# NANO100AN_v1 register map
File version: 1.0
Registers are 32-bit, read-write, reset 0x0 unless marked. A register's access mark holds for its fields unless they carry their own. Offsets are from the block's base; [hi:lo] are bit positions; 'fields as' and 'values as' point back to an identical list.

## SPI0 — SPI Register Map
Base 0x40030000
Same registers: SPI1 0x40130000
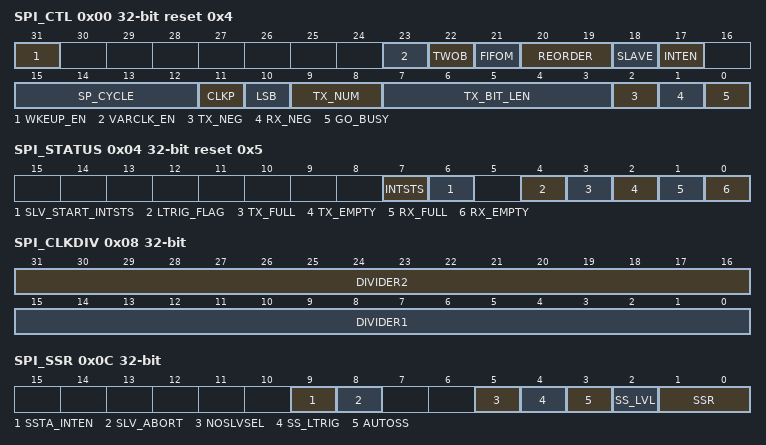
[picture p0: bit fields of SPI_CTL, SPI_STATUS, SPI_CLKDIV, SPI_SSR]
0x00 SPI_CTL reset 0x4 — SPI Control Register
  [31] WKEUP_EN — Wake-Up Enable. Note: When the system enters the power-down mode, the system can be wake-up from the SPI controller when this bit is enabled and if there is any toggle in the SPICLK port. After the system wake-up, this bit must be clear by user to disable the wake-up requirement.
    0=Wake-up function Disabled when the system enters the power-down mode; 1=Wake-up function Enabled
  [23] VARCLK_EN — Variable Clock Enable. Note: Refer to Variable Serial Clock Frequency section.
    0=The serial clock output frequency is fixed and only decided by the value of DIVIDER1; 1=The serial clock output frequency is variable. The output frequency is decided by the value of VARCLK (SPI_VARCLK), DIVIDER1 and DIVIDER2
  [22] TWOB — 2 Data Channel Transfer Mode Active. Note: When enabling TWOB, the setting of TX_NUM must be programmed as 00.
    0=2data channel transfer mode Disabled; 1=2data channel transfer mode Enabled
  [21] FIFOM — FIFO Mode Enable. Note: Refer to Dual FIFO Mode section.
    0=FIFO mode Disabled (in Normal mode); 1=FIFO mode Enabled
  [20:19] REORDER — Reorder Mode Selection. Note: The suspend interval is defined in SP_CYCLE
    0=Disable both byte reorder and suspend functions; 1=Enable byte reorder function and insert a byte suspend interval among each byte. The setting of TX_BIT_LEN must be configured as 00b (32 bits/ word); 2=Enable byte reorder function, but disable byte suspend function; 3=Disable byte reorder function, but insert a suspend interval among each byte. The setting of TX_BIT_LEN must be configured as 00b (32 bits/ word)
  [18] SLAVE — Slave Mode Indication. Note: Refer to Slave Selection section
    0=SPI controller is set as Master mode; 1=SPI controller is set as Slave mode
  [17] INTEN — Interrupt Enable
    0=SPI Interrupt Disabled; 1=SPI Interrupt Enabled
  [15:12] SP_CYCLE — Suspend Interval (Master Only)
  [11] CLKP — Clock Polarity. Note: Refer to Clock Parity section.
    0=The default level of SPICLK is low; 1=The default level of SPICLK is high
  [10] LSB — Send LSB First. Note: Refer to LSB First section.
    0=The MSB, which bit of transmit/receive register depends on the setting of TX_BIT_LEN, is transmitted/received first; 1=The LSB, bit 0 of the SPI_TX0/1, is sent first to the the SPI data output pin, and the first bit received from the SPI data input pin will be put in the LSB position of the SPI_RX register (SPI_RX0/1)
  [9:8] TX_NUM — Number Of Transmit/Receive Transaction
  [7:3] TX_BIT_LEN — Transmit Bit Length
  [2] TX_NEG — Transmit At Negative Edge. Note: Refer to Edge Condition section.
    0=The transmitted data output is changed at the rising edge of SPICLK; 1=The transmitted data output is changed at the falling edge of SPICLK
  [1] RX_NEG — Receive At Negative Edge. Note: Refer to Edge Condition section.
    0=The received data is latched at the rising edge of SPICLK; 1=The received data is latched at the falling edge of SPICLK
  [0] GO_BUSY — Go And Busy Status. During the data transfer, this bit keeps the value of '1'. As the transfer is finished, this bit will be cleared automatically. Note 1: All registers should be set before writing "1" to the GO_BUSY bit in the SPI_CTL register. Note 2: In FIFO mode, this bit will be controlled by hardware. Software should not modify this bit..
    0=Writing this bit "0" to stop data transfer if SPI is transferring; 1=In Master mode, writing "1" to this bit to start the SPI data transfer; In Slave mode, writing '1' to this bit indicates that the salve is ready to communicate with a master
0x04 SPI_STATUS reset 0x5
  [7] INTSTS — Interrupt Status. Note: This bit is read only, but can be cleared by writing "1" to this bit.
    0=Transfer is not finished yet; 1=Transfer is done. The interrupt is requested when the INTEN (SPI_CTL[17]) bit is enabled
  [6] SLV_START_INTSTS — Slave Start Interrupt Status. It is used to indicate that the transfer has started in Slave mode with no slave select.
    0=Slave started transfer no active; 1=Transfer has started in Slave mode with no slave select. It is auto clear by transfer done or writing one clear
  [4] LTRIG_FLAG — Level Trigger Flag (INTERNAL ONLY). In Slave mode, this bit indicates whether the received bit number meets the requirement or not after the current transaction done. Note: This bit is read only
    0=The transferred bit length of one transaction does not meet the specified requirement; 1=The transferred bit length meets the specified requirement which defined in TX_BIT_LEN
  [3] TX_FULL — Transmitted Dual FIFO_FULL Status
    0=Transmitted data FIFO is not full in the dual FIFO mode; 1=Transmitted data FIFO is full in the dual FIFO mode
  [2] TX_EMPTY — Transmitted Dual FIFO_EMPTY Status
    0=Transmitted data FIFO is not empty in the dual FIFO mode; 1=Transmitted data FIFO is empty in the dual FIFO mode
  [1] RX_FULL — Received Dual FIFO_FULL Status
    0=Received data FIFO is not full in dual FIFO mode; 1=Received data FIFO is full in the dual FIFO mode
  [0] RX_EMPTY — Received Dual FIFO_EMPTY Status
    0=Received data FIFO is not empty in the dual FIFO mode; 1=Received data FIFO is empty in the dual FIFO mode
0x08 SPI_CLKDIV — SPI Clock Divider Register
  [31:16] DIVIDER2 — Clock Divider 2 Register. The value is the 2nd 2nd frequency divider of the PCLK to generate the serial clock of SPICLK. The desired frequency is obtained according to the following equation: /
  [15:0] DIVIDER1 — Clock Divider 1 Register. The value is the 1th frequency divider of the PCLK to generate the serial clock of SPICLK. The desired frequency is obtained according to the following equation: / . Note 1: The DIVIDER1 can be set as 0. If the DIVIDER1 is set as zero, the frequency of SPI_SCLK is the same as PCLK in Master mode. Note 2: In Slave mode, the period of SPI clock driven by a master shall equal to or over 5 times the period of PCLK. In other words, the maximum frequency of SPI clock is the fifth of the frequency of slave's PCLK.
0x0C SPI_SSR — SPI Slave Select Register
  [9] SSTA_INTEN — Slave Start Interrupt Enable. Note : Refer to No Slave Select Mode.
    0=Transfer start interrupt Disabled in no slave select mode; 1=Transaction start interrupt Enabled in no slave select mode. It is cleared when the current transfer done or the SLV_START_INTSTS bit cleared (write 1 clear)
  [8] SLV_ABORT — Abort In Slave Mode With No Slave Selected. Note 1:Refer to No Slave Select Mode. Note 2: It is auto clear to "0" by hardware when the abort event is active.
    0=No force the slave abort; 1=Force the current transfer done in no slave select mode
  [5] NOSLVSEL — No Slave Selected In Slave Mode. This is used to ignore the slave select signal in Slave mode. The SPI controller can work on 3 wire interface including SPICLK, SPI_MISO and SPI_MOSI when it is set as a slave device. Note 1: Refer to No Slave Select Mode. Note 2: In no slave select signal mode, the SS_LTRIG (SPI_SSR[4]) shall be set as "1".
    0=The controller is 4-wire bi-direction interface; 1=The controller is 3-wire bi-direction interface in Slave mode. When this bit is set as 1, the controller start to transmit/receive data after the GO_BUSY bit active and the serial clock input
  [4] SS_LTRIG — Slave Select Level Trigger
    0=The input slave select signal is edge-trigger; 1=The slave select signal will be level-trigger. It depends on SS_LVL to decide the signal is active low or active high
  [3] AUTOSS — Automatic Slave Selection (Master Only)
    0=If this bit is set as "0", slave select signals are asserted and de-asserted by setting and clearing related bits in SSR[1:0] register; 1=If this bit is set as "1", SPISS[1:0] signals are generated automatically. It means that device/slave select signal, which is set in SSR[1:0] register is asserted by the SPI controller when transmit/receive is started by setting the GO_BUSY bit, and is de-asserted after each transaction is done
  [2] SS_LVL — Slave Select Active Level. It defines the active level of device/slave select signals (SPISS[1:0]).
    0=The SPISS slave select signal is active Low; 1=The SPISS slave select signal is active High
  [1:0] SSR — Slave Select Active Register (Master Only). If AUTOSS bit (SPI_SSR[3]) is cleared, writing "1" to SSR[0] bit sets the SPISS[0] line to an active state and writing "0" sets the line back to inactive state.( the same as SSR[1] for SPISS[1]). Note 1: This interface can only drive one device/slave at a given time. Therefore, the slave select of the selected device must be set to its active level before starting any read or write transfer. Note 2: SPISS[0] is also defined as device/slave select input in Slave mode. And that the slave select input must be driven by edge active trigger which level depend on the SS_LVL setting, otherwise the SPI slave core will go into dead path until the edge active triggers again or reset the SPI core by software.
    0=Both SPISS[1] and SPISS[0] are inactive; 1=SPISS[1] is inactive, SPISS[0] is active. SPISS[1] is inactive, SPISS[0] is active on the duration of transaction; 2=SPISS[1] is active, SPISS[0] is inactive. SPISS[1] is active on the duration of transaction, SPISS[0] is inactive; 3=Both SPISS[1] and SPISS[0] are active. Both SPISS[1] and SPISS[0] are active on the duration of transaction
0x10 SPI_RX0 ro — SPI Receive Data FIFO Register 0
  [31:0] RXDATA — Receive Data FIFO Register. The received data can be read on it. If the FIFOM bit is set as 1, the user also checks the RX_EMPTY (SPI_STATUS[0]) to check if there is any more received data or not. Note 1: The SPI_RX1 is used only in TWOB bit (SPI_CTL[22]) is set 1. The first channel's received data shall be read from SPI_RX0 and the second channel's received data shall be read from SPI_RX1 in two-bit mode. SPI_RX0 shall be read first in TWOB mode. Note 2: These two registers are read only.
0x14 SPI_RX1 ro — SPI Receive Data FIFO Register 1
  fields as SPI_RX0
0x20 SPI_TX0 wo — SPI Transmit Data FIFO Register 0
  [31:0] TDATA — Transmit Data FIFO Register. The Data Transmit Registers hold the data to be transmitted in the next transfer. The number of valid bits depends on the setting of transmit bit length field of the SPI_CTL register. For example, if TX_BIT_LEN is set to 0x8, the bit SPI_TX[7:0] will be transmitted in next transfer. If TX_BIT_LEN is set to 0x0, the SPI controller will perform a 32-bit transfer. Note: The SPI_TX1 is used only in TWOB bit (SPI_CTL[22]) is set 1. The first channel's transmitted data shall be written into SPI_TX0 and the second channel's transmitted data shall be written into SPI_TX1 in twodata channel mode. SPI_TX0 shall be written first in TWOB mode.
0x24 SPI_TX1 wo — SPI Transmit Data FIFO Register 1
  fields as SPI_TX0
0x34 SPI_VARCLK reset 0x3FFFC3 — SPI Variable Clock Pattern Flag Register
  [31:0] VARCLK — Variable Clock Pattern Flag. The value in this field is the frequency patterns of the SPICLK.
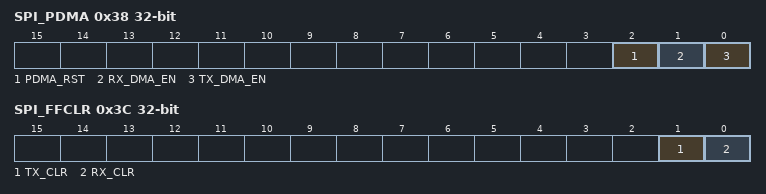
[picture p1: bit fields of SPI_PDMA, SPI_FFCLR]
0x38 SPI_PDMA — SPI PDMA Control Register
  [2] PDMA_RST — PDMA Reset. It is used to reset the SPI PDMA function into default state. Note: It is auto cleared to "0" after the reset function done.
    0=After reset PDMA function or in normal operation; 1=Reset PDMA function
  [1] RX_DMA_EN — Receiver PDMA Enable (PDMA Reads SPI Data To Memory). Note 1: Refer to DMA section for more detail information. Note 2: Hardware will clear this bit to 0 automatically after PDMA transfer done. Note 3: In Slave mode and the FIFO bit is disabled, if the receive PDMA is enabled but the transmit PDMA is disabled, the minimal suspend interval between two successive transactions input is need to be larger than 9 SPI peripheral clock + 4 APB clock for edge mode and 9.5 SPI peripheral clocks + 4 APB clocks.
    0=Receiver PDMA function Disabled; 1=Receiver PDMA function Enabled
  [0] TX_DMA_EN — Transmit PDMA Enable (PDMA Writes Data To SPI). Note 1: Refer to DMA section for more detail information. Note 2: Two transaction need minimal 18 APB clock + 8 SPI peripheral clocks suspend interval in master mode for edge mode and 18 APB clock + 9.5 SPI peripheral clocks for level mode. Note 3: If the 2 data channel function is enabled, the requirement timing shall append 18 APB clock based on the above clock period. Note 4: Hardware will clear this bit to 0 automatically after PDMA transfer done.
    0=Transmit PDMA function Disabled; 1=Transmit PDMA function Enabled
0x3C SPI_FFCLR — SPI FIFO Counter Clear Control Register
  [1] TX_CLR — Transmitting FIFO Counter Clear. Note: This bit is used to clear the transmit counter in FIFO Mode. This bit can be written "1" to clear the transmitting counter and this bit will be cleared to "0" automatically after clearing transmitting counter. After the clear operation, the flag of TX_EMPTY in SPI_STATUS[2] will be set to "1".
    0=No clear the transmitted FIFO; 1=Clear the transmitted FIFO
  [0] RX_CLR — Receiving FIFO Counter Clear. Note: This bit is used to clear the receiver counter in FIFO Mode. This bit can be written "1" to clear the receiver counter and this bit will be cleared to "0" automatically after clearing receiving counter. After the clear operation, the flag of RX_EMPTY in SPI_STATUS[0] will be set to "1".
    0=No clear the received FIFO; 1=Clear the received FIFO
